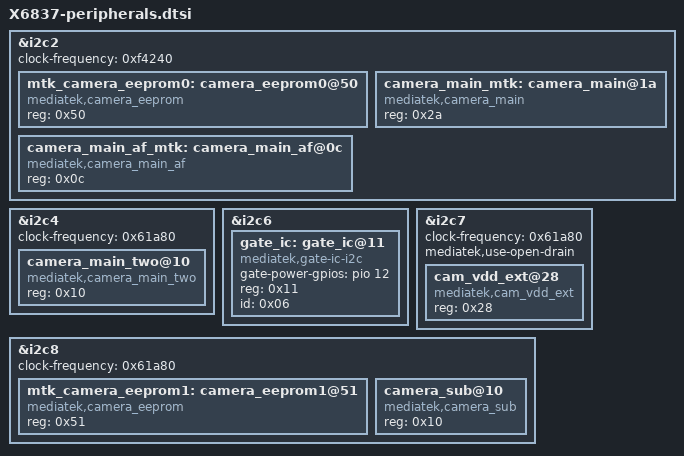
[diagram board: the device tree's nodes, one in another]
&i2c2 {
	status = "okay";
	clock-frequency = <0xf4240>;
	#address-cells = <0x01>;
	#size-cells = <0x00>;

	mtk_camera_eeprom0: camera_eeprom0@50 {
		compatible = "mediatek,camera_eeprom";
		reg = <0x50>;
		status = "okay";
	};

	camera_main_mtk: camera_main@1a {
		compatible = "mediatek,camera_main";
		#thermal-sensor-cells = <0x00>;
		reg = <0x2a>;
		status = "okay";
	};

	camera_main_af_mtk: camera_main_af@0c {
		compatible = "mediatek,camera_main_af";
		reg = <0x0c>;
		status = "okay";
	};
};

&i2c4 {
	status = "okay";
	clock-frequency = <0x61a80>;
	#address-cells = <0x01>;
	#size-cells = <0x00>;

	camera_main_two@10 {
		compatible = "mediatek,camera_main_two";
		#thermal-sensor-cells = <0x00>;
		reg = <0x10>;
		status = "okay";
	};
};

&i2c6 {
	status = "okay";
	#address-cells = <0x01>;
	#size-cells = <0x00>;

	gate_ic: gate_ic@11 {
		compatible = "mediatek,gate-ic-i2c";
		gate-power-gpios = <&pio 12 0>;
		reg = <0x11>;
		id = <0x06>;
		status = "okay";
	};
};

&i2c7 {
	status = "okay";
	clock-frequency = <0x61a80>;
	#address-cells = <0x01>;
	#size-cells = <0x00>;
	mediatek,use-open-drain;

	cam_vdd_ext@28 {
		compatible = "mediatek,cam_vdd_ext";
		reg = <0x28>;
		status = "okay";
	};
};

&i2c8 {
	status = "okay";
	clock-frequency = <0x61a80>;
	#address-cells = <0x01>;
	#size-cells = <0x00>;

	mtk_camera_eeprom1: camera_eeprom1@51 {
		compatible = "mediatek,camera_eeprom";
		reg = <0x51>;
		status = "okay";
	};

	camera_sub@10 {
		compatible = "mediatek,camera_sub";
		#thermal-sensor-cells = <0x00>;
		reg = <0x10>;
		status = "okay";
	};
};
